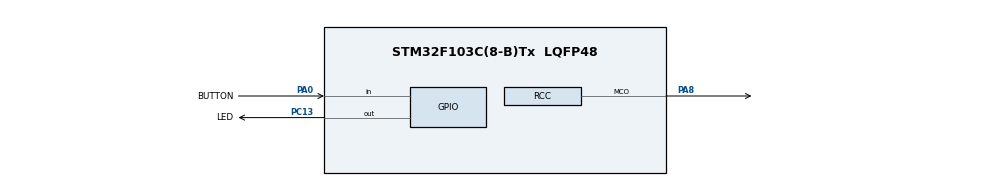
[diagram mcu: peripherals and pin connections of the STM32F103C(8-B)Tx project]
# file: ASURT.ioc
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Mcu.Family=STM32F1
Mcu.Name=STM32F103C(8-B)Tx
Mcu.Package=LQFP48
NVIC.PriorityGroup=NVIC_PRIORITYGROUP_4
PA0-WKUP.GPIO_Label=BUTTON
PA0-WKUP.GPIO_PuPd=GPIO_PULLUP
PA0-WKUP.Signal=GPIO_Input
PA13.Mode=Serial_Wire
PA13.Signal=SYS_JTMS-SWDIO
PA14.Mode=Serial_Wire
PA14.Signal=SYS_JTCK-SWCLK
PA8.Mode=Clock-out
PA8.Signal=RCC_MCO
PC13-TAMPER-RTC.GPIO_Label=LED
PC13-TAMPER-RTC.Signal=GPIO_Output
ProjectManager.HeapSize=0x200
ProjectManager.StackSize=0x400
ProjectManager.TargetToolchain=STM32CubeIDE
RCC.APB1Freq_Value=8000000
RCC.APB2Freq_Value=8000000
board=custom

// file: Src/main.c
/* USER CODE BEGIN Header */
/**
  ******************************************************************************
  * @file           : main.c
  * @brief          : Main program body
  ******************************************************************************
  */
/* USER CODE END Header */
#include "main.h"
#define DEBOUNCE_SAMPLES 5
#define SAMPLE_DELAY_MS 5
#include "gpio.h"

void SystemClock_Config(void);

uint8_t Debounce_Button(GPIO_TypeDef* GPIOx, uint16_t GPIO_Pin);

int main(void)
{

  /* MCU Configuration--------------------------------------------------------*/

  /* Reset of all peripherals, Initializes the Flash interface and the Systick. */
  HAL_Init();

  /* Configure the system clock */
  SystemClock_Config();

  /* Initialize all configured peripherals */
  MX_GPIO_Init();
  /* USER CODE BEGIN 2 */
  uint8_t button_state = 0;
  uint8_t last_button_state = 0;
  /* USER CODE END 2 */

  /* Infinite loop */
  /* USER CODE BEGIN WHILE */
  while (1)
  {
	  /* USER CODE BEGIN WHILE */

	  button_state = Debounce_Button(BUTTON_GPIO_Port, BUTTON_Pin);

	  if (button_state == GPIO_PIN_RESET && last_button_state == GPIO_PIN_SET)
	  {
	    // No of page 228
	    HAL_GPIO_TogglePin(LED_GPIO_Port, LED_Pin);
	  }

	  last_button_state = button_state;
	  /* USER CODE END WHILE */
    /* USER CODE END WHILE */

  }
}

	uint8_t Debounce_Button(GPIO_TypeDef* GPIOx, uint16_t GPIO_Pin)
	{
	  uint8_t stable_count = 0;
	  // No of page 227
	  uint8_t current_state = HAL_GPIO_ReadPin(GPIOx, GPIO_Pin);
	  uint8_t last_state = current_state;

	  for (uint8_t i = 0; i < DEBOUNCE_SAMPLES; i++)
	  {
		  // No of page 50
	    HAL_Delay(SAMPLE_DELAY_MS);

	    // No of page 227
	    current_state = HAL_GPIO_ReadPin(GPIOx, GPIO_Pin);

	    if (current_state == last_state)
	    {
	      stable_count++;
	    }
	    else
	    {

	      stable_count = 0;
	      last_state = current_state;
	    }
	  }

	  if (stable_count >= DEBOUNCE_SAMPLES - 1)
	  {
	    return current_state;
	  }

	  return last_state;
	}

void SystemClock_Config(void)
{
  RCC_OscInitTypeDef RCC_OscInitStruct = {0};
  RCC_ClkInitTypeDef RCC_ClkInitStruct = {0};

  /** Initializes the RCC Oscillators according to the specified parameters
  * in the RCC_OscInitTypeDef structure.
  */
  RCC_OscInitStruct.OscillatorType = RCC_OSCILLATORTYPE_HSI;
  RCC_OscInitStruct.HSIState = RCC_HSI_ON;
  RCC_OscInitStruct.HSICalibrationValue = RCC_HSICALIBRATION_DEFAULT;
  RCC_OscInitStruct.PLL.PLLState = RCC_PLL_NONE;
  if (HAL_RCC_OscConfig(&RCC_OscInitStruct) != HAL_OK)
  {
    Error_Handler();
  }

  /** Initializes the CPU, AHB and APB buses clocks
  */
  RCC_ClkInitStruct.ClockType = RCC_CLOCKTYPE_HCLK|RCC_CLOCKTYPE_SYSCLK
                              |RCC_CLOCKTYPE_PCLK1|RCC_CLOCKTYPE_PCLK2;
  RCC_ClkInitStruct.SYSCLKSource = RCC_SYSCLKSOURCE_HSI;
  RCC_ClkInitStruct.AHBCLKDivider = RCC_SYSCLK_DIV1;
  RCC_ClkInitStruct.APB1CLKDivider = RCC_HCLK_DIV1;
  RCC_ClkInitStruct.APB2CLKDivider = RCC_HCLK_DIV1;

  if (HAL_RCC_ClockConfig(&RCC_ClkInitStruct, FLASH_LATENCY_0) != HAL_OK)
  {
    Error_Handler();
  }
  HAL_RCC_MCOConfig(RCC_MCO, RCC_MCO1SOURCE_SYSCLK, RCC_MCODIV_1);
}

void Error_Handler(void)
{
  __disable_irq();
  while (1)
  {
  }
}
